# EFM32TG11B320F128GQ64 register map
File version: 5.8.2
CPU: CM0PLUS r0p1, little endian, MPU, no FPU, 3 interrupt priority bits
Registers are 32-bit, read-write, reset 0x0 unless marked. A register's access mark holds for its fields unless they carry their own. Offsets are from the block's base; [hi:lo] are bit positions; {n}, {i} and the like mark numbered series.

## LESENSE
Base 0x40055000
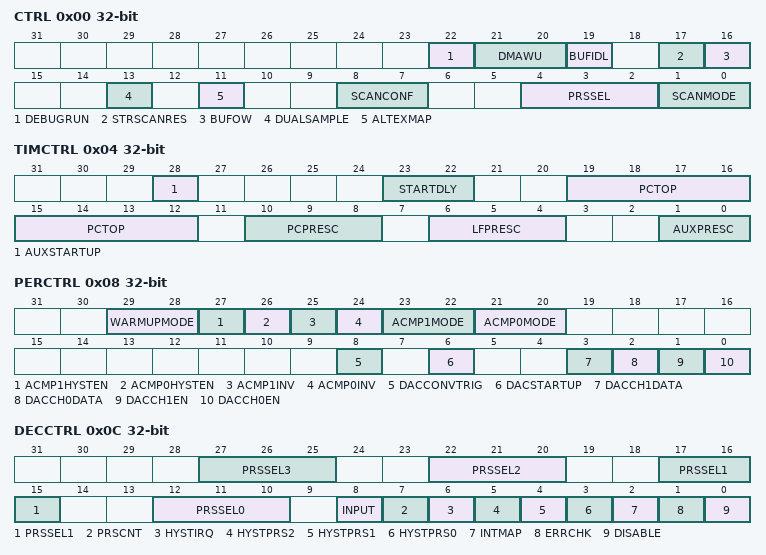
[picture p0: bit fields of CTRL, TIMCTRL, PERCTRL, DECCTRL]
0x00 CTRL — Control Register
  [22] DEBUGRUN — Debug Mode Run Enable
  [21:20] DMAWU — DMA Wake-up From EM2
    0=DISABLE (No DMA wake-up from EM2); 1=BUFDATAV (DMA wake-up from EM2 when data is valid in the result buffer); 2=BUFLEVEL (DMA wake-up from EM2 when the result buffer is full/half-full depending on BUFIDL configuration)
  [19] BUFIDL — Result Buffer Interrupt and DMA Trigger Level
  [17] STRSCANRES — Enable Storing of SCANRES
  [16] BUFOW — Result Buffer Overwrite
  [13] DUALSAMPLE — Enable Dual Sample Mode
  [11] ALTEXMAP — Alternative Excitation Map
  [8:7] SCANCONF — Select Scan Configuration
    0=DIRMAP (The channel configuration register registers used are directly mapped to the channel number.); 1=INVMAP (The channel configuration register registers used are CHX+8_CONF for channels 0-7 and CHX-8_CONF for channels 8-15.); 2=TOGGLE (The channel configuration register registers used toggles between CHX_CONF and CHX+8_CONF when channel x triggers); 3=DECDEF (The decoder state defines the CONF registers to be used.)
  [4:2] PRSSEL — Scan Start PRS Select
    {v}=PRSCH{v} (PRS Channel {v} selected as input) (v=0..7)
  [1:0] SCANMODE — Configure Scan Mode
    0=PERIODIC (A new scan is started each time the period counter overflows); 1=ONESHOT (A single scan is performed when START in CMD is set); 2=PRS (Pulse on PRS channel)
0x04 TIMCTRL — Timing Control Register
  [28] AUXSTARTUP — AUXHFRCO Startup Configuration
  [23:22] STARTDLY — Start Delay Configuration
  [19:12] PCTOP — Period Counter Top Value
  [10:8] PCPRESC — Period Counter Prescaling
    0=DIV1 (The period counter clock frequency is LFACLKLESENSE/1); 1=DIV2 (The period counter clock frequency is LFACLKLESENSE/2); 2=DIV4 (The period counter clock frequency is LFACLKLESENSE/4); 3=DIV8 (The period counter clock frequency is LFACLKLESENSE/8); 4=DIV16 (The period counter clock frequency is LFACLKLESENSE/16); 5=DIV32 (The period counter clock frequency is LFACLKLESENSE/32); 6=DIV64 (The period counter clock frequency is LFACLKLESENSE/64); 7=DIV128 (The period counter clock frequency is LFACLKLESENSE/128)
  [6:4] LFPRESC — Prescaling Factor for Low Frequency Timer
    0=DIV1 (Low frequency timer is clocked with LFACLKLESENSE/1); 1=DIV2 (Low frequency timer is clocked with LFACLKLESENSE/2); 2=DIV4 (Low frequency timer is clocked with LFACLKLESENSE/4); 3=DIV8 (Low frequency timer is clocked with LFACLKLESENSE/8); 4=DIV16 (Low frequency timer is clocked with LFACLKLESENSE/16); 5=DIV32 (Low frequency timer is clocked with LFACLKLESENSE/32); 6=DIV64 (Low frequency timer is clocked with LFACLKLESENSE/64); 7=DIV128 (Low frequency timer is clocked with LFACLKLESENSE/128)
  [1:0] AUXPRESC — Prescaling Factor for High Frequency Timer
    0=DIV1 (High frequency timer is clocked with AUXHFRCO/1); 1=DIV2 (High frequency timer is clocked with AUXHFRCO/2); 2=DIV4 (High frequency timer is clocked with AUXHFRCO/4); 3=DIV8 (High frequency timer is clocked with AUXHFRCO/8)
0x08 PERCTRL — Peripheral Control Register
  [29:28] WARMUPMODE — ACMP and VDAC Duty Cycle Mode
    0=NORMAL (The analog comparators and VDAC are shut down when LESENSE is idle); 1=KEEPACMPWARM (The analog comparators are kept powered up when LESENSE is idle); 2=KEEPDACWARM (The VDAC is kept powered up when LESENSE is idle); 3=KEEPACMPDACWARM (The analog comparators and VDAC are kept powered up when LESENSE is idle)
  [27] ACMP1HYSTEN — ACMP1 Hysteresis Enable
  [26] ACMP0HYSTEN — ACMP0 Hysteresis Enable
  [25] ACMP1INV — Invert Analog Comparator 1 Output
  [24] ACMP0INV — Invert Analog Comparator 0 Output
  [23:22] ACMP1MODE
    0=DISABLE (LESENSE does not control ACMP1); 1=MUX (LESENSE controls the input mux (POSSEL) of ACMP1); 2=MUXTHRES (LESENSE controls the input mux and the threshold value (VDDLEVEL) of ACMP1)
  [21:20] ACMP0MODE
    0=DISABLE (LESENSE does not control ACMP0); 1=MUX (LESENSE controls the input mux (POSSEL) of ACMP0); 2=MUXTHRES (LESENSE controls the input mux (POSSEL) and the threshold value (VDDLEVEL) of ACMP0)
  [8] DACCONVTRIG — VDAC Conversion Trigger Configuration
  [6] DACSTARTUP — VDAC Startup Configuration
  [3] DACCH1DATA — VDAC CH1 Data Selection
  [2] DACCH0DATA — VDAC CH0 Data Selection
  [1] DACCH1EN — VDAC CH1 Enable
  [0] DACCH0EN — VDAC CH0 Enable
0x0C DECCTRL — Decoder Control Register
  [5n+12:5n+10] PRSSEL{n} (n=0..3) — LESENSE Decoder PRS Input {n} Configuration
    {v}=PRSCH{v} (PRS Channel {v} selected as input) (v=0..7)
  [8] INPUT — LESENSE Decoder Input Configuration
  [7] PRSCNT — Enable Count Mode on Decoder PRS Channels 0 and 1
  [6] HYSTIRQ — Enable Decoder Hysteresis on Interrupt Requests
  [5] HYSTPRS2 — Enable Decoder Hysteresis on PRS2 Output
  [4] HYSTPRS1 — Enable Decoder Hysteresis on PRS1 Output
  [3] HYSTPRS0 — Enable Decoder Hysteresis on PRS0 Output
  [2] INTMAP — Enable Decoder to Channel Interrupt Mapping
  [1] ERRCHK — Enable Check of Current State
  [0] DISABLE — Disable the Decoder
0x10 BIASCTRL — Bias Control Register
  [1:0] BIASMODE — Select Bias Mode
    0=DONTTOUCH (Bias module is controlled by the EMU and is not affected by LESENSE); 1=DUTYCYCLE (Bias module duty cycled between low power and high accuracy mode); 2=HIGHACC (Bias module always in high accuracy mode)
0x14 EVALCTRL — LESENSE Evaluation Control
  [15:0] WINSIZE — Sliding Window and Step Detection Size
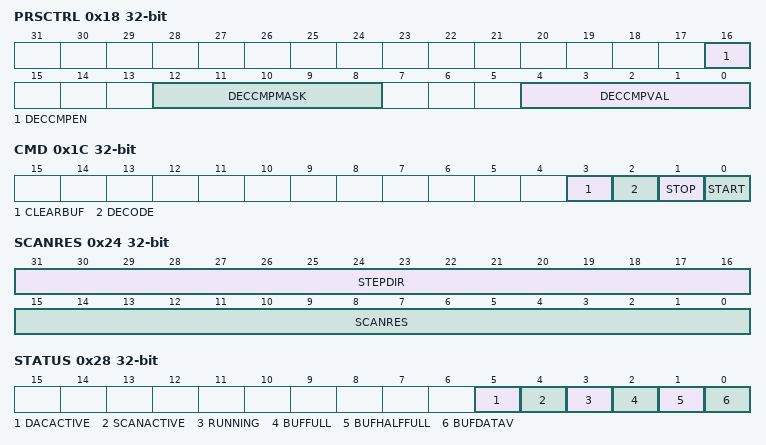
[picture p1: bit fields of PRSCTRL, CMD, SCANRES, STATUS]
0x18 PRSCTRL — PRS Control Register
  [16] DECCMPEN — Enable PRS Output DECCMP
  [12:8] DECCMPMASK — Decoder State Compare Value Mask
  [4:0] DECCMPVAL — Decoder State Compare Value
0x1C CMD wo — Command Register
  [3] CLEARBUF — Clear Result Buffer
  [2] DECODE — Start Decoder
  [1] STOP — Stop Scanning of Sensors
  [0] START — Start Scanning of Sensors
0x20 CHEN — Channel Enable Register
  [15:0] CHEN — Enable Scan Channel
0x24 SCANRES — Scan Result Register
  [31:16] STEPDIR — Direction of Previous Step Detection
  [15:0] SCANRES — Scan Results
0x28 STATUS ro
  [5] DACACTIVE — LESENSE VDAC Interface is Active
  [4] SCANACTIVE — LESENSE Scan Active
  [3] RUNNING — LESENSE Periodic Counter Running
  [2] BUFFULL — Result Buffer Full
  [1] BUFHALFFULL — Result Buffer Half Full
  [0] BUFDATAV — Result Data Valid
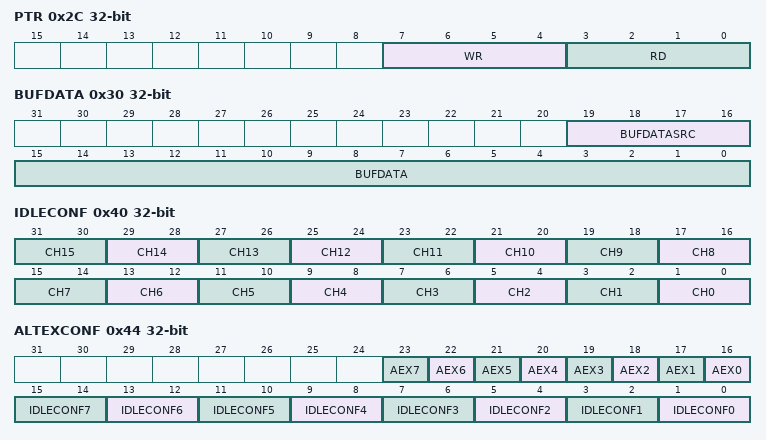
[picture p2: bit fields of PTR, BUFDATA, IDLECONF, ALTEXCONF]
0x2C PTR ro — Result Buffer Pointers
  [7:4] WR — Result Buffer Write Pointer
  [3:0] RD — Result Buffer Read Pointer
0x30 BUFDATA ro read-has-side-effects — Result Buffer Data Register
  [19:16] BUFDATASRC — Result Data Source
  [15:0] BUFDATA — Result Data
0x34 CURCH ro — Current Channel Index
  [3:0] CURCH
0x38 DECSTATE — Current Decoder State
  [4:0] DECSTATE
0x3C SENSORSTATE — Decoder Input Register
  [3:0] SENSORSTATE
0x40 IDLECONF — GPIO Idle Phase Configuration
  [2n+1:2n] CH{n} (n=0..15) — Channel {n} Idle Phase Configuration
    0=DISABLE (CH{n} output is disabled in idle phase); 1=HIGH (CH{n} output is high in idle phase); 2=LOW (CH{n} output is low in idle phase); 3=DAC (CH{n} output is connected to VDAC output in idle phase. Note that this mode is only available on channels 0, 1, 2, 3, 12, 13, 14, 15)
0x44 ALTEXCONF — Alternative Excite Pin Configuration
  [n+16] AEX{n} (n=0..7) — ALTEX{n} Always Excite Enable
  [2n+1:2n] IDLECONF{n} (n=0..7) — ALTEX{n} Idle Phase Configuration
    0=DISABLE (ALTEX{n} output is disabled in idle phase); 1=HIGH (ALTEX{n} output is high in idle phase); 2=LOW (ALTEX{n} output is low in idle phase)
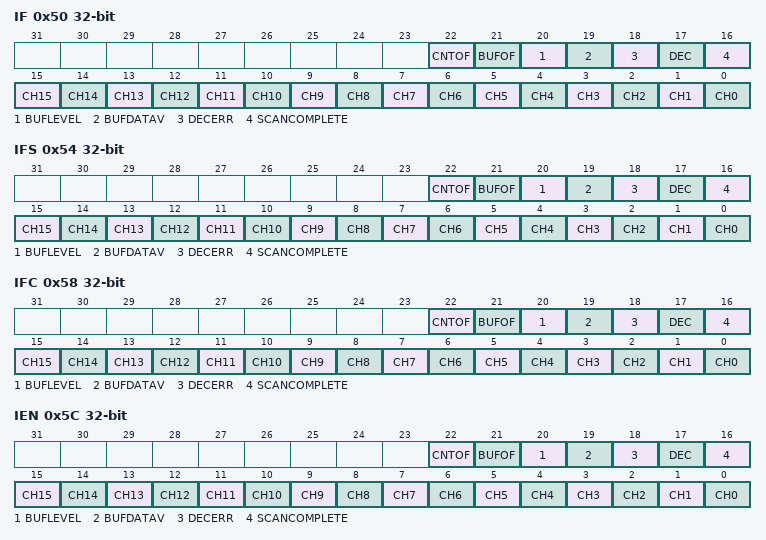
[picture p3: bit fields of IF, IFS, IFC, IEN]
0x50 IF ro — Interrupt Flag Register
  [22] CNTOF — CNTOF Interrupt Flag
  [21] BUFOF — BUFOF Interrupt Flag
  [20] BUFLEVEL — BUFLEVEL Interrupt Flag
  [19] BUFDATAV — BUFDATAV Interrupt Flag
  [18] DECERR — DECERR Interrupt Flag
  [17] DEC — DEC Interrupt Flag
  [16] SCANCOMPLETE — SCANCOMPLETE Interrupt Flag
  [n] CH{n} (n=0..15) — CH{n} Interrupt Flag
0x54 IFS wo — Interrupt Flag Set Register
  [22] CNTOF — Set CNTOF Interrupt Flag
  [21] BUFOF — Set BUFOF Interrupt Flag
  [20] BUFLEVEL — Set BUFLEVEL Interrupt Flag
  [19] BUFDATAV — Set BUFDATAV Interrupt Flag
  [18] DECERR — Set DECERR Interrupt Flag
  [17] DEC — Set DEC Interrupt Flag
  [16] SCANCOMPLETE — Set SCANCOMPLETE Interrupt Flag
  [n] CH{n} (n=0..15) — Set CH{n} Interrupt Flag
0x58 IFC wo — Interrupt Flag Clear Register
  [22] CNTOF — Clear CNTOF Interrupt Flag
  [21] BUFOF — Clear BUFOF Interrupt Flag
  [20] BUFLEVEL — Clear BUFLEVEL Interrupt Flag
  [19] BUFDATAV — Clear BUFDATAV Interrupt Flag
  [18] DECERR — Clear DECERR Interrupt Flag
  [17] DEC — Clear DEC Interrupt Flag
  [16] SCANCOMPLETE — Clear SCANCOMPLETE Interrupt Flag
  [n] CH{n} (n=0..15) — Clear CH{n} Interrupt Flag
0x5C IEN — Interrupt Enable Register
  [22] CNTOF — CNTOF Interrupt Enable
  [21] BUFOF — BUFOF Interrupt Enable
  [20] BUFLEVEL — BUFLEVEL Interrupt Enable
  [19] BUFDATAV — BUFDATAV Interrupt Enable
  [18] DECERR — DECERR Interrupt Enable
  [17] DEC — DEC Interrupt Enable
  [16] SCANCOMPLETE — SCANCOMPLETE Interrupt Enable
  [n] CH{n} (n=0..15) — CH{n} Interrupt Enable
0x60 SYNCBUSY ro — Synchronization Busy Register
  [7] CMD — CMD Register Busy
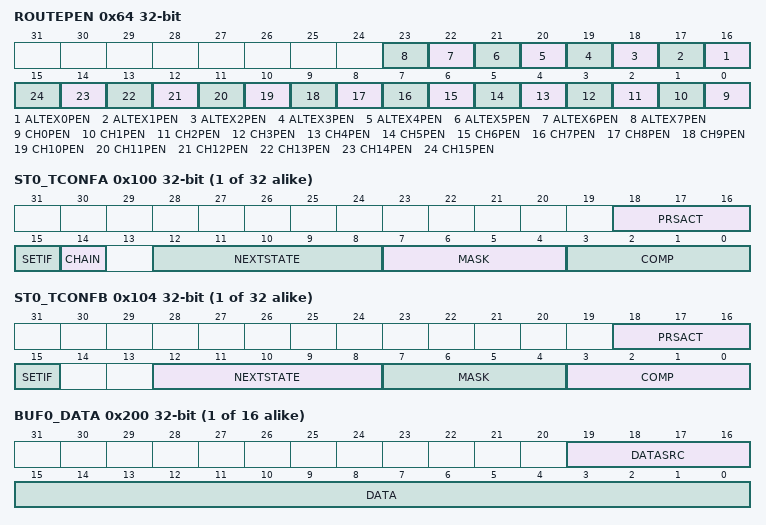
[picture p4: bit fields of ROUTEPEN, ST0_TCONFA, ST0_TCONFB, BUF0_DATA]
0x64 ROUTEPEN — I/O Routing Register
  [n+16] ALTEX{n}PEN (n=0..7) — ALTEX{n} Pin Enable
  [n] CH{n}PEN (n=0..15) — CH{n} Pin Enable
{0x100+8i} ST{i}_TCONFA (i=0..31) — State Transition Configuration a
  [18:16] PRSACT — Configure Transition Action
  [15] SETIF — Set Interrupt Flag Enable
  [14] CHAIN — Enable State Descriptor Chaining
  [12:8] NEXTSTATE — Next State Index
  [7:4] MASK — Sensor Mask
  [3:0] COMP — Sensor Compare Value
{0x104+8i} ST{i}_TCONFB (i=0..31) — State Transition Configuration B
  [18:16] PRSACT — Configure Transition Action
  [15] SETIF — Set Interrupt Flag
  [12:8] NEXTSTATE — Next State Index
  [7:4] MASK — Sensor Mask
  [3:0] COMP — Sensor Compare Value
{0x200+4i} BUF{i}_DATA (i=0..15) — Scan Results
  [19:16] DATASRC ro — Result Data Source
  [15:0] DATA — Scan Result Buffer
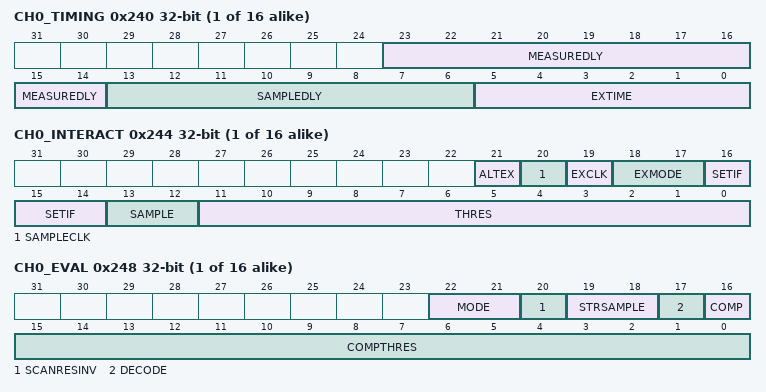
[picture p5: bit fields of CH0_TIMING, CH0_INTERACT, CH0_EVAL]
{0x240+0x10*i} CH{i}_TIMING (i=0..15) — Scan Configuration
  [23:14] MEASUREDLY — Set Measure Delay
  [13:6] SAMPLEDLY — Set Sample Delay
  [5:0] EXTIME — Set Excitation Time
{0x244+0x10*i} CH{i}_INTERACT (i=0..15) — Scan Configuration
  [21] ALTEX — Use Alternative Excite Pin
  [20] SAMPLECLK — Select Clock Used for Timing of Sample Delay
  [19] EXCLK — Select Clock Used for Excitation Timing
  [18:17] EXMODE — Set GPIO Mode
    0=DISABLE (Disabled); 1=HIGH (Push Pull, GPIO is driven high); 2=LOW (Push Pull, GPIO is driven low); 3=DACOUT (VDAC output)
  [16:14] SETIF — Enable Interrupt Generation
    0=NONE (No interrupt is generated); 1=LEVEL (Set interrupt flag if the sensor triggers.); 2=POSEDGE (Set interrupt flag on positive edge of the sensor state); 3=NEGEDGE (Set interrupt flag on negative edge of the sensor state); 4=BOTHEDGES (Set interrupt flag on both edges of the sensor state)
  [13:12] SAMPLE — Select Sample Mode
    0=ACMPCOUNT (Counter output will be used in evaluation); 1=ACMP (ACMP output will be used in evaluation); 2=ADC (ADC output will be used in evaluation); 3=ADCDIFF (Differential ADC output will be used in evaluation)
  [11:0] THRES — ACMP Threshold or VDAC Data
{0x248+0x10*i} CH{i}_EVAL (i=0..15) — Scan Configuration
  [22:21] MODE — Configure Evaluation Mode
    0=THRES (Threshold comparison is used to evaluate sensor result); 1=SLIDINGWIN (Sliding window is used to evaluate sensor result); 2=STEPDET (Step detection is used to evaluate sensor result)
  [20] SCANRESINV — Enable Inversion of Result
  [19:18] STRSAMPLE — Enable Storing of Sensor Sample in Result Buffer
    0=DISABLE (Nothing will be stored in the result buffer.); 1=DATA (The sensor sample data will be stored in the result buffer.); 2=DATASRC (The data source (i.e., the channel) will be stored alongside the sensor sample data.)
  [17] DECODE — Send Result to Decoder
  [16] COMP — Select Mode for Threshold Comparison
  [15:0] COMPTHRES — Decision Threshold for Sensor Data

## Notices in the file
# License
Copyright 2019 Silicon Laboratories Inc. www.silabs.com
SPDX-License-Identifier: Zlib
The licensor of this software is Silicon Laboratories Inc.
This software is provided 'as-is', without any express or implied
warranty. In no event will the authors be held liable for any damages
arising from the use of this software.
Permission is granted to anyone to use this software for any purpose,
including commercial applications, and to alter it and redistribute it
freely, subject to the following restrictions:
1. The origin of this software must not be misrepresented; you must not
claim that you wrote the original software. If you use this software
in a product, an acknowledgment in the product documentation would be
appreciated but is not required.
2. Altered source versions must be plainly marked as such, and must not be
misrepresented as being the original software.
3. This notice may not be removed or altered from any source distribution.
